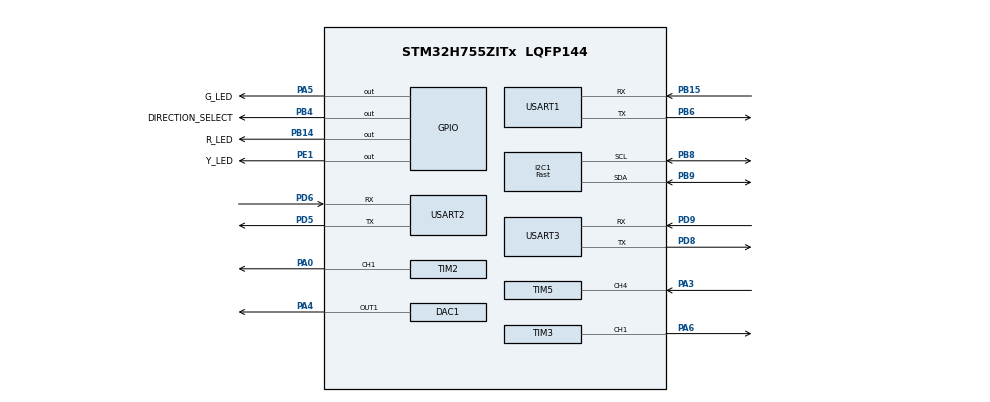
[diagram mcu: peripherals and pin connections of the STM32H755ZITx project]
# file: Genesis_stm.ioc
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CORTEX_M7.default_mode_Activation=1
CortexM4.IPs=CORTEX_M4\:I,DEBUG,FATFS_M4\:I,FREERTOS_M4\:I,IWDG2\:I,OPENAMP_M4\:I,PDM2PCM_M4\:I,PWR,RCC,RESMGR_UTILITY,SYS_M4\:I,USB_DEVICE_M4\:I,USB_HOST_M4\:I,VREFBUF,WWDG2\:I,GPIO,DMA,BDMA,MDMA,NVIC2\:I
CortexM7.IPs=CORTEX_M7\:I,DEBUG\:I,FATFS_M7\:I,FREERTOS_M7\:I,IWDG1\:I,OPENAMP_M7\:I,PDM2PCM_M7\:I,PWR\:I,RCC\:I,RESMGR_UTILITY\:I,SYS\:I,USB_DEVICE_M7\:I,USB_HOST_M7\:I,VREFBUF\:I,WWDG1\:I,GPIO\:I,DMA\:I,BDMA\:I,MDMA\:I,NVIC1\:I,USART3\:I,USART2\:I,I2C1\:I,TIM2\:I,TIM5\:I,USART1\:I,DAC1\:I,TIM3\:I
CortexM7.Pins=PA5,PB14,PB4 (NJTRST),PE1
DAC1.DAC_Channel-DAC_OUT1=DAC_CHANNEL_1
Dma.I2C1_TX.3.Direction=DMA_MEMORY_TO_PERIPH
Dma.I2C1_TX.3.EventEnable=DISABLE
Dma.I2C1_TX.3.FIFOMode=DMA_FIFOMODE_DISABLE
Dma.I2C1_TX.3.Instance=DMA1_Stream3
Dma.I2C1_TX.3.MemDataAlignment=DMA_MDATAALIGN_BYTE
Dma.I2C1_TX.3.MemInc=DMA_MINC_ENABLE
Dma.I2C1_TX.3.Mode=DMA_NORMAL
Dma.I2C1_TX.3.PeriphDataAlignment=DMA_PDATAALIGN_BYTE
Dma.I2C1_TX.3.PeriphInc=DMA_PINC_DISABLE
Dma.I2C1_TX.3.Polarity=HAL_DMAMUX_REQ_GEN_RISING
Dma.I2C1_TX.3.Priority=DMA_PRIORITY_LOW
Dma.I2C1_TX.3.RequestNumber=1
Dma.I2C1_TX.3.SignalID=NONE
Dma.I2C1_TX.3.SyncEnable=DISABLE
Dma.I2C1_TX.3.SyncPolarity=HAL_DMAMUX_SYNC_NO_EVENT
Dma.I2C1_TX.3.SyncRequestNumber=1
Dma.I2C1_TX.3.SyncSignalID=NONE
Dma.Request0=TIM5_CH4
Dma.Request1=USART2_TX
Dma.Request2=USART2_RX
Dma.Request3=I2C1_TX
Dma.Request4=USART1_RX
Dma.TIM5_CH4.0.Direction=DMA_PERIPH_TO_MEMORY
Dma.TIM5_CH4.0.EventEnable=DISABLE
Dma.TIM5_CH4.0.FIFOMode=DMA_FIFOMODE_DISABLE
Dma.TIM5_CH4.0.Instance=DMA1_Stream0
Dma.TIM5_CH4.0.MemDataAlignment=DMA_MDATAALIGN_WORD
Dma.TIM5_CH4.0.MemInc=DMA_MINC_ENABLE
Dma.TIM5_CH4.0.Mode=DMA_CIRCULAR
Dma.TIM5_CH4.0.PeriphDataAlignment=DMA_PDATAALIGN_WORD
Dma.TIM5_CH4.0.PeriphInc=DMA_PINC_DISABLE
Dma.TIM5_CH4.0.Polarity=HAL_DMAMUX_REQ_GEN_RISING
Dma.TIM5_CH4.0.Priority=DMA_PRIORITY_HIGH
Dma.TIM5_CH4.0.RequestNumber=1
Dma.TIM5_CH4.0.SignalID=NONE
Dma.TIM5_CH4.0.SyncEnable=DISABLE
Dma.TIM5_CH4.0.SyncPolarity=HAL_DMAMUX_SYNC_NO_EVENT
Dma.TIM5_CH4.0.SyncRequestNumber=1
Dma.TIM5_CH4.0.SyncSignalID=NONE
Dma.USART1_RX.4.Direction=DMA_PERIPH_TO_MEMORY
Dma.USART1_RX.4.EventEnable=DISABLE
Dma.USART1_RX.4.FIFOMode=DMA_FIFOMODE_DISABLE
Dma.USART1_RX.4.Instance=DMA1_Stream5
Dma.USART1_RX.4.MemDataAlignment=DMA_MDATAALIGN_BYTE
Dma.USART1_RX.4.MemInc=DMA_MINC_ENABLE
Dma.USART1_RX.4.Mode=DMA_NORMAL
Dma.USART1_RX.4.PeriphDataAlignment=DMA_PDATAALIGN_BYTE
Dma.USART1_RX.4.PeriphInc=DMA_PINC_DISABLE
Dma.USART1_RX.4.Polarity=HAL_DMAMUX_REQ_GEN_RISING
Dma.USART1_RX.4.Priority=DMA_PRIORITY_MEDIUM
Dma.USART1_RX.4.RequestNumber=1
Dma.USART1_RX.4.SignalID=NONE
Dma.USART1_RX.4.SyncEnable=DISABLE
Dma.USART1_RX.4.SyncPolarity=HAL_DMAMUX_SYNC_NO_EVENT
Dma.USART1_RX.4.SyncRequestNumber=1
Dma.USART1_RX.4.SyncSignalID=NONE
Dma.USART2_RX.2.Direction=DMA_PERIPH_TO_MEMORY
Dma.USART2_RX.2.EventEnable=DISABLE
Dma.USART2_RX.2.FIFOMode=DMA_FIFOMODE_DISABLE
Dma.USART2_RX.2.Instance=DMA1_Stream2
Dma.USART2_RX.2.MemDataAlignment=DMA_MDATAALIGN_BYTE
Dma.USART2_RX.2.MemInc=DMA_MINC_ENABLE
Dma.USART2_RX.2.Mode=DMA_NORMAL
Dma.USART2_RX.2.PeriphDataAlignment=DMA_PDATAALIGN_BYTE
Dma.USART2_RX.2.PeriphInc=DMA_PINC_DISABLE
Dma.USART2_RX.2.Polarity=HAL_DMAMUX_REQ_GEN_RISING
Dma.USART2_RX.2.Priority=DMA_PRIORITY_LOW
Dma.USART2_RX.2.RequestNumber=1
Dma.USART2_RX.2.SignalID=NONE
Dma.USART2_RX.2.SyncEnable=DISABLE
Dma.USART2_RX.2.SyncPolarity=HAL_DMAMUX_SYNC_NO_EVENT
Dma.USART2_RX.2.SyncRequestNumber=1
Dma.USART2_RX.2.SyncSignalID=NONE
Dma.USART2_TX.1.Direction=DMA_MEMORY_TO_PERIPH
Dma.USART2_TX.1.EventEnable=DISABLE
Dma.USART2_TX.1.FIFOMode=DMA_FIFOMODE_DISABLE
Dma.USART2_TX.1.Instance=DMA1_Stream1
Dma.USART2_TX.1.MemDataAlignment=DMA_MDATAALIGN_BYTE
Dma.USART2_TX.1.MemInc=DMA_MINC_ENABLE
Dma.USART2_TX.1.Mode=DMA_NORMAL
Dma.USART2_TX.1.PeriphDataAlignment=DMA_PDATAALIGN_BYTE
Dma.USART2_TX.1.PeriphInc=DMA_PINC_DISABLE
Dma.USART2_TX.1.Polarity=HAL_DMAMUX_REQ_GEN_RISING
Dma.USART2_TX.1.Priority=DMA_PRIORITY_LOW
Dma.USART2_TX.1.RequestNumber=1
Dma.USART2_TX.1.SignalID=NONE
Dma.USART2_TX.1.SyncEnable=DISABLE
Dma.USART2_TX.1.SyncPolarity=HAL_DMAMUX_SYNC_NO_EVENT
Dma.USART2_TX.1.SyncRequestNumber=1
Dma.USART2_TX.1.SyncSignalID=NONE
I2C1.I2C_Speed_Mode=I2C_Fast
I2C1.Timing=0x00401959
Mcu.Family=STM32H7
Mcu.Name=STM32H755ZITx
Mcu.Package=LQFP144
NVIC1.DMA1_Stream0_IRQn=true\:7\:0\:true\:false\:true\:true\:true\:true
NVIC1.DMA1_Stream1_IRQn=true\:6\:0\:true\:false\:true\:true\:true\:true
NVIC1.DMA1_Stream2_IRQn=true\:6\:0\:true\:false\:true\:true\:true\:true
NVIC1.DMA1_Stream3_IRQn=true\:6\:0\:true\:false\:true\:true\:true\:true
NVIC1.DMA1_Stream5_IRQn=true\:6\:0\:true\:false\:true\:true\:true\:true
NVIC1.I2C1_ER_IRQn=true\:0\:0\:false\:false\:true\:true\:true\:true
NVIC1.I2C1_EV_IRQn=true\:6\:0\:true\:false\:true\:true\:true\:true
NVIC1.PriorityGroup=NVIC_PRIORITYGROUP_4
NVIC1.TIM5_IRQn=true\:6\:0\:true\:false\:true\:true\:true\:true
NVIC1.USART1_IRQn=true\:6\:0\:true\:false\:true\:true\:true\:true
NVIC1.USART2_IRQn=true\:6\:0\:true\:false\:true\:true\:true\:true
NVIC2.PriorityGroup=NVIC_PRIORITYGROUP_4
PA0.PinAttribute=CortexM7
PA0.Signal=S_TIM2_CH1_ETR
PA3.PinAttribute=CortexM7
PA3.Signal=S_TIM5_CH4
PA4.PinAttribute=CortexM7
PA4.Signal=COMP_DAC11_group
PA5.GPIO_Label=G_LED
PA5.PinAttribute=CortexM7
PA5.Signal=GPIO_Output
PA6.PinAttribute=CortexM7
PA6.Signal=S_TIM3_CH1
PB14.GPIO_Label=R_LED
PB14.PinAttribute=CortexM7
PB14.Signal=GPIO_Output
PB15.Mode=Asynchronous
PB15.PinAttribute=CortexM7
PB15.Signal=USART1_RX
PB4\ (NJTRST).GPIO_Label=DIRECTION_SELECT
PB4\ (NJTRST).PinAttribute=CortexM7
PB4\ (NJTRST).Signal=GPIO_Output
PB6.Mode=Asynchronous
PB6.PinAttribute=CortexM7
PB6.Signal=USART1_TX
PB8.Mode=I2C
PB8.PinAttribute=CortexM7
PB8.Signal=I2C1_SCL
PB9.Mode=I2C
PB9.PinAttribute=CortexM7
PB9.Signal=I2C1_SDA
PD5.Mode=Asynchronous
PD5.PinAttribute=CortexM7
PD5.Signal=USART2_TX
PD6.Mode=Asynchronous
PD6.PinAttribute=CortexM7
PD6.Signal=USART2_RX
PD8.Mode=Asynchronous
PD8.PinAttribute=CortexM7
PD8.Signal=USART3_TX
PD9.Mode=Asynchronous
PD9.PinAttribute=CortexM7
PD9.Signal=USART3_RX
PE1.GPIO_Label=Y_LED
PE1.PinAttribute=CortexM7
PE1.Signal=GPIO_Output
ProjectManager.HeapSize=M4-0x200,M7-0x800
ProjectManager.StackSize=M4-0x400,M7-0x1000
ProjectManager.TargetToolchain=Makefile
RCC.ADCFreq_Value=129000000
RCC.APB1Freq_Value=50000000
RCC.APB2Freq_Value=50000000
RCC.APB3Freq_Value=100000000
RCC.APB4Freq_Value=100000000
RCC.CortexFreq_Value=200000000
RCC.D1PPRE=RCC_APB3_DIV2
RCC.D2PPRE1=RCC_APB1_DIV4
RCC.D2PPRE2=RCC_APB2_DIV4
RCC.D3PPRE=RCC_APB4_DIV2
RCC.DIVM1=4
RCC.DIVN1=25
RCC.DIVQ1=4
RCC.HCLKFreq_Value=200000000
RCC.PLL2FRACN=0
RCC.PLL3FRACN=0
RCC.PLLFRACN=0
RCC.SYSCLKFreq_VALUE=200000000
RCC.SYSCLKSource=RCC_SYSCLKSOURCE_PLLCLK
RCC.USBFreq_Value=100000000
SH.COMP_DAC11_group.0=DAC1_OUT1,DAC_OUT1
SH.S_TIM2_CH1_ETR.0=TIM2_CH1,PWM Generation1 CH1
SH.S_TIM3_CH1.0=TIM3_CH1,PWM Generation1 CH1
SH.S_TIM5_CH4.0=TIM5_CH4,Input_Capture4_from_TI4
SYS.userName=SYS_M7
TIM2.Channel-PWM\ Generation1\ CH1=TIM_CHANNEL_1
TIM2.Period=320000
TIM2.Prescaler=4
TIM3.Channel-PWM\ Generation1\ CH1=TIM_CHANNEL_1
TIM3.Prescaler=4
TIM5.Channel-Input_Capture4_from_TI4=TIM_CHANNEL_4
USART1.VirtualMode-Asynchronous=VM_ASYNC
USART2.VirtualMode-Asynchronous=VM_ASYNC
USART3.VirtualMode-Asynchronous=VM_ASYNC
VP_SYS_M4_VS_Systick.Mode=SysTick
VP_TIM2_VS_ClockSourceINT.Mode=Internal
VP_TIM3_VS_ClockSourceINT.Mode=Internal
VP_TIM5_VS_ClockSourceINT.Mode=Internal
board=custom

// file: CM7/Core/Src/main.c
/* USER CODE BEGIN Header */
/**
  ******************************************************************************
  * @file           : main.c
  * @brief          : Main program body
  ******************************************************************************
  * @attention
  *
  * Copyright (c) 2024 STMicroelectronics.
  * All rights reserved.
  *
  * This software is licensed under terms that can be found in the LICENSE file
  * in the root directory of this software component.
  * If no LICENSE file comes with this software, it is provided AS-IS.
  *
  ******************************************************************************
  */
/* USER CODE END Header */
#include "main.h"
#include "dac.h"
#include "dma.h"
#include "i2c.h"
#include "tim.h"
#include "usart.h"
#include "gpio.h"

/* USER CODE BEGIN Includes */

#include "AppMainCM7.h"

/* USER CODE END Includes */

/* USER CODE BEGIN PD */

#ifndef HSEM_ID_0
#define HSEM_ID_0 (0U) /* HW semaphore 0*/
#endif

/* USER CODE END PD */

void SystemClock_Config(void);
static void MPU_Config(void);

int main(void)
{

/* USER CODE BEGIN Boot_Mode_Sequence_0 */
  int32_t timeout;
/* USER CODE END Boot_Mode_Sequence_0 */

  /* MPU Configuration--------------------------------------------------------*/
  MPU_Config();

/* USER CODE BEGIN Boot_Mode_Sequence_1 */
  // ! CPU2 is currently not used - Disabled in option bytes
  /* Wait until CPU2 boots and enters in stop mode or timeout*/
  // timeout = 0xFFFF;
  // while((__HAL_RCC_GET_FLAG(RCC_FLAG_D2CKRDY) != RESET) && (timeout-- > 0));
  // if ( timeout < 0 )
  // {
  // Error_Handler();
  // }
/* USER CODE END Boot_Mode_Sequence_1 */
  /* MCU Configuration--------------------------------------------------------*/

  /* Reset of all peripherals, Initializes the Flash interface and the Systick. */
  HAL_Init();

  /* Configure the system clock */
  SystemClock_Config();
/* USER CODE BEGIN Boot_Mode_Sequence_2 */
/* When system initialization is finished, Cortex-M7 will release Cortex-M4 by means of
HSEM notification */
/*HW semaphore Clock enable*/
// __HAL_RCC_HSEM_CLK_ENABLE();
// /*Take HSEM */
// HAL_HSEM_FastTake(HSEM_ID_0);
// /*Release HSEM in order to notify the CPU2(CM4)*/
// HAL_HSEM_Release(HSEM_ID_0,0);
// /* wait until CPU2 wakes up from stop mode */
// timeout = 0xFFFF;
// while((__HAL_RCC_GET_FLAG(RCC_FLAG_D2CKRDY) == RESET) && (timeout-- > 0));
// if ( timeout < 0 )
// {
// Error_Handler();
// }
/* USER CODE END Boot_Mode_Sequence_2 */

  /* Initialize all configured peripherals */
  MX_GPIO_Init();
  MX_DMA_Init();
  MX_TIM2_Init();
  MX_USART2_UART_Init();
  MX_USART3_UART_Init();
  MX_TIM5_Init();
  MX_I2C1_Init();
  MX_USART1_UART_Init();
  MX_DAC1_Init();
  MX_TIM3_Init();
  /* USER CODE BEGIN 2 */

  // Set NVIC priority grouping for FreeRTOS compatibility
  HAL_NVIC_SetPriorityGrouping(NVIC_PRIORITYGROUP_4);

  AppCM7_Main();
  /* USER CODE END 2 */

  /* Infinite loop */
  while (1)
  {

  }
}

void SystemClock_Config(void)
{
  RCC_OscInitTypeDef RCC_OscInitStruct = {0};
  RCC_ClkInitTypeDef RCC_ClkInitStruct = {0};

  /** Supply configuration update enable
  */
  HAL_PWREx_ConfigSupply(PWR_DIRECT_SMPS_SUPPLY);

  /** Configure the main internal regulator output voltage
  */
  __HAL_PWR_VOLTAGESCALING_CONFIG(PWR_REGULATOR_VOLTAGE_SCALE3);

  while(!__HAL_PWR_GET_FLAG(PWR_FLAG_VOSRDY)) {}

  /** Initializes the RCC Oscillators according to the specified parameters
  * in the RCC_OscInitTypeDef structure.
  */
  RCC_OscInitStruct.OscillatorType = RCC_OSCILLATORTYPE_HSI;
  RCC_OscInitStruct.HSIState = RCC_HSI_DIV1;
  RCC_OscInitStruct.HSICalibrationValue = RCC_HSICALIBRATION_DEFAULT;
  RCC_OscInitStruct.PLL.PLLState = RCC_PLL_ON;
  RCC_OscInitStruct.PLL.PLLSource = RCC_PLLSOURCE_HSI;
  RCC_OscInitStruct.PLL.PLLM = 4;
  RCC_OscInitStruct.PLL.PLLN = 25;
  RCC_OscInitStruct.PLL.PLLP = 2;
  RCC_OscInitStruct.PLL.PLLQ = 4;
  RCC_OscInitStruct.PLL.PLLR = 2;
  RCC_OscInitStruct.PLL.PLLRGE = RCC_PLL1VCIRANGE_3;
  RCC_OscInitStruct.PLL.PLLVCOSEL = RCC_PLL1VCOWIDE;
  RCC_OscInitStruct.PLL.PLLFRACN = 0;
  if (HAL_RCC_OscConfig(&RCC_OscInitStruct) != HAL_OK)
  {
    Error_Handler();
  }

  /** Initializes the CPU, AHB and APB buses clocks
  */
  RCC_ClkInitStruct.ClockType = RCC_CLOCKTYPE_HCLK|RCC_CLOCKTYPE_SYSCLK
                              |RCC_CLOCKTYPE_PCLK1|RCC_CLOCKTYPE_PCLK2
                              |RCC_CLOCKTYPE_D3PCLK1|RCC_CLOCKTYPE_D1PCLK1;
  RCC_ClkInitStruct.SYSCLKSource = RCC_SYSCLKSOURCE_PLLCLK;
  RCC_ClkInitStruct.SYSCLKDivider = RCC_SYSCLK_DIV1;
  RCC_ClkInitStruct.AHBCLKDivider = RCC_HCLK_DIV1;
  RCC_ClkInitStruct.APB3CLKDivider = RCC_APB3_DIV2;
  RCC_ClkInitStruct.APB1CLKDivider = RCC_APB1_DIV4;
  RCC_ClkInitStruct.APB2CLKDivider = RCC_APB2_DIV4;
  RCC_ClkInitStruct.APB4CLKDivider = RCC_APB4_DIV2;

  if (HAL_RCC_ClockConfig(&RCC_ClkInitStruct, FLASH_LATENCY_4) != HAL_OK)
  {
    Error_Handler();
  }
}

 /* MPU Configuration */

void MPU_Config(void)
{
  MPU_Region_InitTypeDef MPU_InitStruct = {0};

  /* Disables the MPU */
  HAL_MPU_Disable();

  /** Initializes and configures the Region and the memory to be protected
  */
  MPU_InitStruct.Enable = MPU_REGION_ENABLE;
  MPU_InitStruct.Number = MPU_REGION_NUMBER0;
  MPU_InitStruct.BaseAddress = 0x0;
  MPU_InitStruct.Size = MPU_REGION_SIZE_4GB;
  MPU_InitStruct.SubRegionDisable = 0x87;
  MPU_InitStruct.TypeExtField = MPU_TEX_LEVEL0;
  MPU_InitStruct.AccessPermission = MPU_REGION_NO_ACCESS;
  MPU_InitStruct.DisableExec = MPU_INSTRUCTION_ACCESS_DISABLE;
  MPU_InitStruct.IsShareable = MPU_ACCESS_SHAREABLE;
  MPU_InitStruct.IsCacheable = MPU_ACCESS_NOT_CACHEABLE;
  MPU_InitStruct.IsBufferable = MPU_ACCESS_NOT_BUFFERABLE;

  HAL_MPU_ConfigRegion(&MPU_InitStruct);
  /* Enables the MPU */
  HAL_MPU_Enable(MPU_PRIVILEGED_DEFAULT);

}

void Error_Handler(void)
{
  /* USER CODE BEGIN Error_Handler_Debug */
  /* User can add his own implementation to report the HAL error return state */
  HAL_GPIO_WritePin(GPIOB, GPIO_PIN_14, GPIO_PIN_SET);
  __disable_irq();
  while (1)
  {
  }
  /* USER CODE END Error_Handler_Debug */
}
